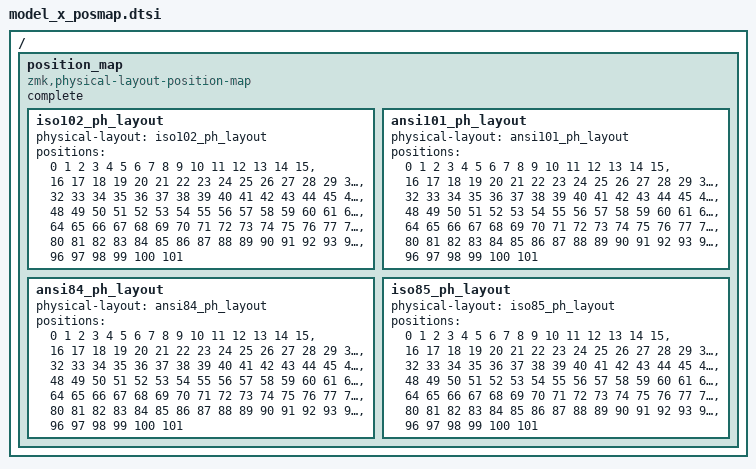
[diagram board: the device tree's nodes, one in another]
// Position mapping made with this tool-> https://zmk-layout-helper.netlify.app/
/ {
    position_map {
        compatible = "zmk,physical-layout-position-map";

        complete;

        iso102_ph_layout {
            physical-layout = <&iso102_ph_layout>;
            positions
                = < 0   1   2   3   4   5   6   7   8   9  10  11  12  13  14  15>
                , <16  17  18  19  20  21  22  23  24  25  26  27  28  29  30  31>
                , <32  33  34  35  36  37  38  39  40  41  42  43  44  45  46  47>
                , <48  49  50  51  52  53  54  55  56  57  58  59  60  61  62  63>
                , <64  65  66  67  68  69  70  71  72  73  74  75  76  77  78  79>
                , <80  81  82  83  84  85  86  87  88  89  90  91  92  93  94  95>
                , <96  97  98  99 100 101>
                ;
        };

        ansi101_ph_layout {
            physical-layout = <&ansi101_ph_layout>;
            positions
                = < 0   1   2   3   4   5   6   7   8   9  10  11  12  13  14  15>
                , <16  17  18  19  20  21  22  23  24  25  26  27  28  29  30  31>
                , <32  33  34  35  36  37  38  39  40  41  42  43  44  45  46  47>
                , <48  49  50  51  52  53  54  55  56  57  58  59  60  61  62  63>
                , <64  65  66  67  68  69  70  71  72  73  74  75  76  77  78  79>
                , <80  81  82  83  84  85  86  87  88  89  90  91  92  93  94  95>
                , <96  97  98  99 100 101>
                ;
        };

        ansi84_ph_layout {
            physical-layout = <&ansi84_ph_layout>;
            positions
                = < 0   1   2   3   4   5   6   7   8   9  10  11  12  13  14  15>
                , <16  17  18  19  20  21  22  23  24  25  26  27  28  29  30  31>
                , <32  33  34  35  36  37  38  39  40  41  42  43  44  45  46  47>
                , <48  49  50  51  52  53  54  55  56  57  58  59  60  61  62  63>
                , <64  65  66  67  68  69  70  71  72  73  74  75  76  77  78  79>
                , <80  81  82  83  84  85  86  87  88  89  90  91  92  93  94  95>
                , <96  97  98  99 100 101>
                ;
        };
        
        iso85_ph_layout {
            physical-layout = <&iso85_ph_layout>;
            positions
                = < 0   1   2   3   4   5   6   7   8   9  10  11  12  13  14  15>
                , <16  17  18  19  20  21  22  23  24  25  26  27  28  29  30  31>
                , <32  33  34  35  36  37  38  39  40  41  42  43  44  45  46  47>
                , <48  49  50  51  52  53  54  55  56  57  58  59  60  61  62  63>
                , <64  65  66  67  68  69  70  71  72  73  74  75  76  77  78  79>
                , <80  81  82  83  84  85  86  87  88  89  90  91  92  93  94  95>
                , <96  97  98  99 100 101>
                ;
        };
    };
};
